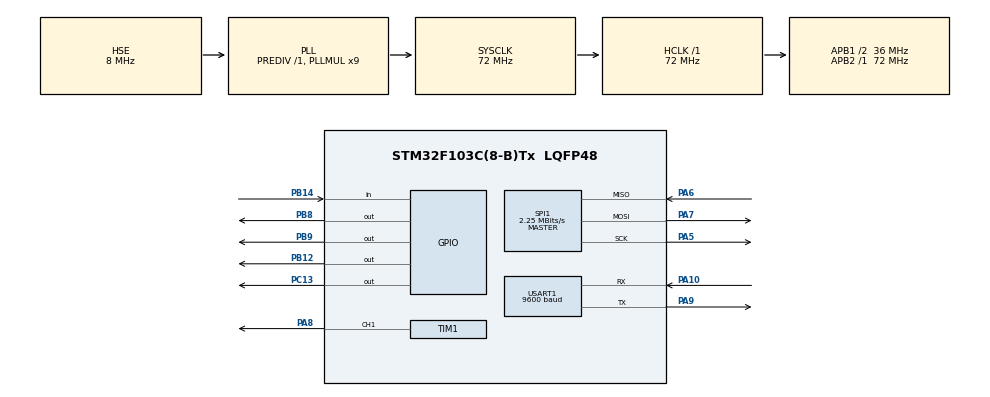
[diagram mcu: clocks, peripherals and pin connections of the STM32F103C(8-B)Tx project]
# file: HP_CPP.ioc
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Mcu.Family=STM32F1
RCC.PLLSourceVirtual=RCC_PLLSOURCE_HSE
PA6.Mode=Full_Duplex_Master
PA7.Mode=Full_Duplex_Master
PD1-OSC_OUT.Mode=HSE-External-Oscillator
PA10.Mode=Asynchronous
SPI1.VirtualType=VM_MASTER
USART1.BaudRate=9600
PB8.GPIO_PuPd=GPIO_PULLDOWN
PC13-TAMPER-RTC.Signal=GPIO_Output
RCC.USBPrescaler=RCC_USBCLKSOURCE_PLL_DIV1_5
NVIC.TIM1_UP_IRQn=true\:0\:0\:false\:false\:true\:true\:true
PD0-OSC_IN.Signal=RCC_OSC_IN
TIM1.Pulse-PWM\ Generation1\ CH1=50
RCC.APB1CLKDivider=RCC_HCLK_DIV2
RCC.SYSCLKSource=RCC_SYSCLKSOURCE_PLLCLK
ProjectManager.StackSize=0x400
PD1-OSC_OUT.Signal=RCC_OSC_OUT
PA13.Signal=SYS_JTMS-SWDIO
PA9.Mode=Asynchronous
TIM1.Prescaler=5
SH.S_TIM1_CH1.0=TIM1_CH1,PWM Generation1 CH1
ProjectManager.TargetToolchain=STM32CubeIDE
SPI1.Direction=SPI_DIRECTION_2LINES
RCC.HCLKFreq_Value=72000000
RCC.APB2TimFreq_Value=72000000
PA9.Signal=USART1_TX
USART1.Parity=PARITY_EVEN
SPI1.CalculateBaudRate=2.25 MBits/s
RCC.USBFreq_Value=48000000
RCC.AHBFreq_Value=72000000
PD0-OSC_IN.Mode=HSE-External-Oscillator
PB14.Signal=GPIO_Input
PA5.Signal=SPI1_SCK
board=custom
RCC.PLLMUL=RCC_PLL_MUL9
NVIC.SPI1_IRQn=true\:3\:0\:true\:false\:true\:true\:true
RCC.APB2Freq_Value=72000000
TIM1.Channel-PWM\ Generation1\ CH1=TIM_CHANNEL_1
SPI1.Mode=SPI_MODE_MASTER
PA14.Mode=Serial_Wire
PA8.Signal=S_TIM1_CH1
PA13.Mode=Serial_Wire
Mcu.Name=STM32F103C(8-B)Tx
RCC.SYSCLKFreq_VALUE=72000000
Mcu.Package=LQFP48
PB9.Signal=GPIO_Output
PA6.Signal=SPI1_MISO
PC13-TAMPER-RTC.GPIO_PuPd=GPIO_PULLDOWN
USART1.VirtualMode=VM_ASYNC
PA10.Signal=USART1_RX
PA14.Signal=SYS_JTCK-SWCLK
PB9.GPIO_PuPd=GPIO_PULLDOWN
NVIC.TIM1_BRK_IRQn=true\:0\:0\:false\:false\:true\:true\:true
ProjectManager.HeapSize=0x200
NVIC.PriorityGroup=NVIC_PRIORITYGROUP_4
RCC.APB1TimFreq_Value=72000000
PB8.Signal=GPIO_Output
TIM1.Period=255
NVIC.USART1_IRQn=true\:3\:0\:true\:false\:true\:true\:true
RCC.APB1Freq_Value=36000000
SPI1.BaudRatePrescaler=SPI_BAUDRATEPRESCALER_32
PB12.Signal=GPIO_Output
PA5.Mode=Full_Duplex_Master
PA7.Signal=SPI1_MOSI

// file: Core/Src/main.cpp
/* USER CODE BEGIN Header */
/**
  ******************************************************************************
  * @file           : main.c
  * @brief          : Main program body
  ******************************************************************************
  * @attention
  *
  * <h2><center>&copy; Copyright (c) 2021 STMicroelectronics.
  * All rights reserved.</center></h2>
  *
  * This software component is licensed by ST under BSD 3-Clause license,
  * the "License"; You may not use this file except in compliance with the
  * License. You may obtain a copy of the License at:
  *                        opensource.org/licenses/BSD-3-Clause
  *
  ******************************************************************************
  */
/* USER CODE END Header */
#include "main.h"

/* USER CODE BEGIN Includes */
#include "AT45DB161D.hpp"
#include "FlashProgramator.h"
#include "Song.h"
#include "SongPlayer.h"
/* USER CODE END Includes */

SPI_HandleTypeDef hspi1;

TIM_HandleTypeDef htim1;

UART_HandleTypeDef huart1;

void SystemClock_Config(void);
static void MX_GPIO_Init(void);
static void MX_SPI1_Init(void);
static void MX_USART1_UART_Init(void);
static void MX_TIM1_Init(void);

int main(void)
{

  /* MCU Configuration--------------------------------------------------------*/

  /* Reset of all peripherals, Initializes the Flash interface and the Systick. */
  HAL_Init();

  /* Configure the system clock */
  SystemClock_Config();

  /* Initialize all configured peripherals */
  MX_GPIO_Init();
  MX_SPI1_Init();
  MX_USART1_UART_Init();
  MX_TIM1_Init();
  /* USER CODE BEGIN 2 */
  AT45DB161D* flash = new AT45DB161D(&hspi1);

   //  FlashProgramator* flashProgramator = new FlashProgramator();
   //  flashProgramator->Program(flash, &huart1);

  Song* song = new Song();
  song->Load(flash);

  SongPlayer* songPlayer = new SongPlayer();
  songPlayer->Play(song, &htim1);

  /* USER CODE END 2 */

  /* Infinite loop */
  while (1)
  {

  }
}

void SystemClock_Config(void)
{
  RCC_OscInitTypeDef RCC_OscInitStruct = {0};
  RCC_ClkInitTypeDef RCC_ClkInitStruct = {0};

  /** Initializes the RCC Oscillators according to the specified parameters
  * in the RCC_OscInitTypeDef structure.
  */
  RCC_OscInitStruct.OscillatorType = RCC_OSCILLATORTYPE_HSE;
  RCC_OscInitStruct.HSEState = RCC_HSE_ON;
  RCC_OscInitStruct.HSEPredivValue = RCC_HSE_PREDIV_DIV1;
  RCC_OscInitStruct.HSIState = RCC_HSI_ON;
  RCC_OscInitStruct.PLL.PLLState = RCC_PLL_ON;
  RCC_OscInitStruct.PLL.PLLSource = RCC_PLLSOURCE_HSE;
  RCC_OscInitStruct.PLL.PLLMUL = RCC_PLL_MUL9;
  if (HAL_RCC_OscConfig(&RCC_OscInitStruct) != HAL_OK)
  {
    Error_Handler();
  }
  /** Initializes the CPU, AHB and APB buses clocks
  */
  RCC_ClkInitStruct.ClockType = RCC_CLOCKTYPE_HCLK|RCC_CLOCKTYPE_SYSCLK
                              |RCC_CLOCKTYPE_PCLK1|RCC_CLOCKTYPE_PCLK2;
  RCC_ClkInitStruct.SYSCLKSource = RCC_SYSCLKSOURCE_PLLCLK;
  RCC_ClkInitStruct.AHBCLKDivider = RCC_SYSCLK_DIV1;
  RCC_ClkInitStruct.APB1CLKDivider = RCC_HCLK_DIV2;
  RCC_ClkInitStruct.APB2CLKDivider = RCC_HCLK_DIV1;

  if (HAL_RCC_ClockConfig(&RCC_ClkInitStruct, FLASH_LATENCY_2) != HAL_OK)
  {
    Error_Handler();
  }
}

static void MX_SPI1_Init(void)
{

  /* SPI1 parameter configuration*/
  hspi1.Instance = SPI1;
  hspi1.Init.Mode = SPI_MODE_MASTER;
  hspi1.Init.Direction = SPI_DIRECTION_2LINES;
  hspi1.Init.DataSize = SPI_DATASIZE_8BIT;
  hspi1.Init.CLKPolarity = SPI_POLARITY_LOW;
  hspi1.Init.CLKPhase = SPI_PHASE_1EDGE;
  hspi1.Init.NSS = SPI_NSS_SOFT;
  hspi1.Init.BaudRatePrescaler = SPI_BAUDRATEPRESCALER_32;
  hspi1.Init.FirstBit = SPI_FIRSTBIT_MSB;
  hspi1.Init.TIMode = SPI_TIMODE_DISABLE;
  hspi1.Init.CRCCalculation = SPI_CRCCALCULATION_DISABLE;
  hspi1.Init.CRCPolynomial = 10;
  if (HAL_SPI_Init(&hspi1) != HAL_OK)
  {
    Error_Handler();
  }

}

static void MX_TIM1_Init(void)
{

  TIM_MasterConfigTypeDef sMasterConfig = {0};
  TIM_OC_InitTypeDef sConfigOC = {0};
  TIM_BreakDeadTimeConfigTypeDef sBreakDeadTimeConfig = {0};

  htim1.Instance = TIM1;
  htim1.Init.Prescaler = 5;
  htim1.Init.CounterMode = TIM_COUNTERMODE_UP;
  htim1.Init.Period = 255;
  htim1.Init.ClockDivision = TIM_CLOCKDIVISION_DIV1;
  htim1.Init.RepetitionCounter = 0;
  htim1.Init.AutoReloadPreload = TIM_AUTORELOAD_PRELOAD_DISABLE;
  if (HAL_TIM_PWM_Init(&htim1) != HAL_OK)
  {
    Error_Handler();
  }
  sMasterConfig.MasterOutputTrigger = TIM_TRGO_RESET;
  sMasterConfig.MasterSlaveMode = TIM_MASTERSLAVEMODE_DISABLE;
  if (HAL_TIMEx_MasterConfigSynchronization(&htim1, &sMasterConfig) != HAL_OK)
  {
    Error_Handler();
  }
  sConfigOC.OCMode = TIM_OCMODE_PWM1;
  sConfigOC.Pulse = 50;
  sConfigOC.OCPolarity = TIM_OCPOLARITY_HIGH;
  sConfigOC.OCNPolarity = TIM_OCNPOLARITY_HIGH;
  sConfigOC.OCFastMode = TIM_OCFAST_DISABLE;
  sConfigOC.OCIdleState = TIM_OCIDLESTATE_RESET;
  sConfigOC.OCNIdleState = TIM_OCNIDLESTATE_RESET;
  if (HAL_TIM_PWM_ConfigChannel(&htim1, &sConfigOC, TIM_CHANNEL_1) != HAL_OK)
  {
    Error_Handler();
  }
  sBreakDeadTimeConfig.OffStateRunMode = TIM_OSSR_DISABLE;
  sBreakDeadTimeConfig.OffStateIDLEMode = TIM_OSSI_DISABLE;
  sBreakDeadTimeConfig.LockLevel = TIM_LOCKLEVEL_OFF;
  sBreakDeadTimeConfig.DeadTime = 0;
  sBreakDeadTimeConfig.BreakState = TIM_BREAK_DISABLE;
  sBreakDeadTimeConfig.BreakPolarity = TIM_BREAKPOLARITY_HIGH;
  sBreakDeadTimeConfig.AutomaticOutput = TIM_AUTOMATICOUTPUT_DISABLE;
  if (HAL_TIMEx_ConfigBreakDeadTime(&htim1, &sBreakDeadTimeConfig) != HAL_OK)
  {
    Error_Handler();
  }
  HAL_TIM_MspPostInit(&htim1);

}

static void MX_USART1_UART_Init(void)
{

  huart1.Instance = USART1;
  huart1.Init.BaudRate = 9600;
  huart1.Init.WordLength = UART_WORDLENGTH_8B;
  huart1.Init.StopBits = UART_STOPBITS_1;
  huart1.Init.Parity = UART_PARITY_EVEN;
  huart1.Init.Mode = UART_MODE_TX_RX;
  huart1.Init.HwFlowCtl = UART_HWCONTROL_NONE;
  huart1.Init.OverSampling = UART_OVERSAMPLING_16;
  if (HAL_UART_Init(&huart1) != HAL_OK)
  {
    Error_Handler();
  }

}

static void MX_GPIO_Init(void)
{
  GPIO_InitTypeDef GPIO_InitStruct = {0};

  /* GPIO Ports Clock Enable */
  __HAL_RCC_GPIOC_CLK_ENABLE();
  __HAL_RCC_GPIOD_CLK_ENABLE();
  __HAL_RCC_GPIOA_CLK_ENABLE();
  __HAL_RCC_GPIOB_CLK_ENABLE();

  /*Configure GPIO pin Output Level */
  HAL_GPIO_WritePin(GPIOC, GPIO_PIN_13, GPIO_PIN_RESET);

  /*Configure GPIO pin Output Level */
  HAL_GPIO_WritePin(GPIOB, GPIO_PIN_12|GPIO_PIN_8|GPIO_PIN_9, GPIO_PIN_RESET);

  /*Configure GPIO pin : PC13 */
  GPIO_InitStruct.Pin = GPIO_PIN_13;
  GPIO_InitStruct.Mode = GPIO_MODE_OUTPUT_PP;
  GPIO_InitStruct.Pull = GPIO_PULLDOWN;
  GPIO_InitStruct.Speed = GPIO_SPEED_FREQ_LOW;
  HAL_GPIO_Init(GPIOC, &GPIO_InitStruct);

  /*Configure GPIO pin : PB12 */
  GPIO_InitStruct.Pin = GPIO_PIN_12;
  GPIO_InitStruct.Mode = GPIO_MODE_OUTPUT_PP;
  GPIO_InitStruct.Pull = GPIO_NOPULL;
  GPIO_InitStruct.Speed = GPIO_SPEED_FREQ_LOW;
  HAL_GPIO_Init(GPIOB, &GPIO_InitStruct);

  /*Configure GPIO pin : PB14 */
  GPIO_InitStruct.Pin = GPIO_PIN_14;
  GPIO_InitStruct.Mode = GPIO_MODE_INPUT;
  GPIO_InitStruct.Pull = GPIO_NOPULL;
  HAL_GPIO_Init(GPIOB, &GPIO_InitStruct);

  /*Configure GPIO pins : PB8 PB9 */
  GPIO_InitStruct.Pin = GPIO_PIN_8|GPIO_PIN_9;
  GPIO_InitStruct.Mode = GPIO_MODE_OUTPUT_PP;
  GPIO_InitStruct.Pull = GPIO_PULLDOWN;
  GPIO_InitStruct.Speed = GPIO_SPEED_FREQ_LOW;
  HAL_GPIO_Init(GPIOB, &GPIO_InitStruct);

}

void Error_Handler(void)
{
  __disable_irq();
  while (1)
  {
  }
}

/************************ (C) COPYRIGHT STMicroelectronics *****END OF FILE****/
